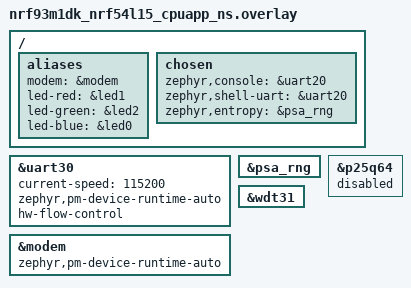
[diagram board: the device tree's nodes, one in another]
/*
 * Copyright (c) 2026 Nordic Semiconductor ASA
 *
 * SPDX-License-Identifier: LicenseRef-Nordic-5-Clause
 */


/ {
	aliases {
		modem = &modem;
		led-red = &led1;
		led-green = &led2;
		led-blue = &led0;
	};
	chosen {
		/* Switch console to uart20 */
		zephyr,console = &uart20;
		zephyr,shell-uart = &uart20;
		zephyr,entropy = &psa_rng;
	};
};

/* Zephyr modem UART <-> nRF91 Serial Modem UART */
&uart30 {
	status = "okay";
	current-speed = <115200>;
	zephyr,pm-device-runtime-auto;
	hw-flow-control;
};

&modem {
	status = "okay";
	zephyr,pm-device-runtime-auto;
	/* CMUX runtime power save is left off. The nRF93M1 rejects the in-band PSC command, so
	 * the link would sleep on DTR/RI alone, and a command that is slow to answer, such as
	 * AT%WIFISCAN, then loses its reply and the PPP link drops with NO CARRIER.
	 */
};

&psa_rng {
	status = "okay";
};

/* External SPI flash (Puya P25Q64 on board HW v0.4.0+) is unused. */
&p25q64 {
	status = "disabled";
};

/* Hardware fallback for CONFIG_TASK_WDT_HW_FALLBACK */
&wdt31 {
	status = "okay";
};

/* Flash/SRAM partitioning */
#include "nrf93m1dk_partitions.dtsi"
